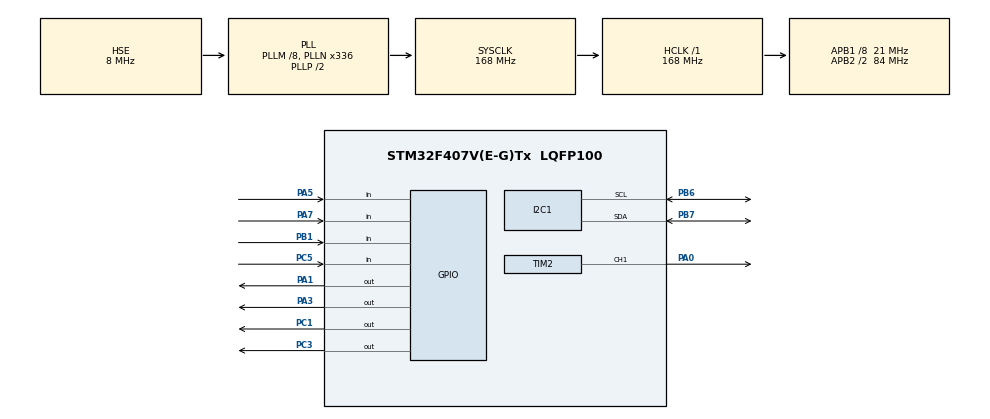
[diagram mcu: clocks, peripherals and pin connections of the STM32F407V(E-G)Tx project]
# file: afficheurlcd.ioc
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Mcu.Family=STM32F4
Mcu.Name=STM32F407V(E-G)Tx
Mcu.Package=LQFP100
NVIC.PriorityGroup=NVIC_PRIORITYGROUP_0
PA0-WKUP.Signal=S_TIM2_CH1_ETR
PA1.Signal=GPIO_Output
PA13.Mode=Serial_Wire
PA13.Signal=SYS_JTMS-SWDIO
PA14.Mode=Serial_Wire
PA14.Signal=SYS_JTCK-SWCLK
PA3.Signal=GPIO_Output
PA5.Signal=GPIO_Input
PA7.Signal=GPIO_Input
PB1.Signal=GPIO_Input
PB6.Mode=I2C
PB6.Signal=I2C1_SCL
PB7.Mode=I2C
PB7.Signal=I2C1_SDA
PC1.Signal=GPIO_Output
PC3.Signal=GPIO_Output
PC5.Signal=GPIO_Input
PH0-OSC_IN.Mode=HSE-External-Oscillator
PH0-OSC_IN.Signal=RCC_OSC_IN
PH1-OSC_OUT.Mode=HSE-External-Oscillator
PH1-OSC_OUT.Signal=RCC_OSC_OUT
ProjectManager.HeapSize=0x200
ProjectManager.StackSize=0x400
ProjectManager.TargetToolchain=STM32CubeIDE
RCC.48MHZClocksFreq_Value=48000000
RCC.AHBFreq_Value=168000000
RCC.APB1CLKDivider=RCC_HCLK_DIV8
RCC.APB1Freq_Value=21000000
RCC.APB1TimFreq_Value=42000000
RCC.APB2CLKDivider=RCC_HCLK_DIV2
RCC.APB2Freq_Value=84000000
RCC.APB2TimFreq_Value=168000000
RCC.CortexFreq_Value=168000000
RCC.HCLKFreq_Value=168000000
RCC.HSE_VALUE=8000000
RCC.HSI_VALUE=16000000
RCC.LSE_VALUE=32768
RCC.PLLM=8
RCC.PLLN=336
RCC.PLLQ=7
RCC.PLLSourceVirtual=RCC_PLLSOURCE_HSE
RCC.SYSCLKFreq_VALUE=168000000
RCC.SYSCLKSource=RCC_SYSCLKSOURCE_PLLCLK
RCC.VCOOutputFreq_Value=336000000
SH.S_TIM2_CH1_ETR.0=TIM2_CH1,PWM Generation1 CH1
TIM2.Channel-PWM\ Generation1\ CH1=TIM_CHANNEL_1
TIM2.Period=1000
TIM2.Prescaler=840
board=STM32F407G-DISC1

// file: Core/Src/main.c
/* USER CODE BEGIN Header */
/**
  ******************************************************************************
  * @file           : main.c
  * @brief          : Main program body
  ******************************************************************************
  * @attention
  *
  * Copyright (c) 2024 STMicroelectronics.
  * All rights reserved.
  *
  * This software is licensed under terms that can be found in the LICENSE file
  * in the root directory of this software component.
  * If no LICENSE file comes with this software, it is provided AS-IS.
  *
  ******************************************************************************
  */
/* USER CODE END Header */
#include "main.h"
#include "STM32F407_KeypadDriver.h"
#include "i2c-lcd.h"
#include<string.h>

I2C_HandleTypeDef hi2c1;

TIM_HandleTypeDef htim2;

void SystemClock_Config(void);
static void MX_GPIO_Init(void);
static void MX_I2C1_Init(void);
static void MX_TIM2_Init(void);

/* USER CODE BEGIN 0 */
#define PASSWORD "1234"
/* USER CODE END 0 */

int main(void)
{

  /* MCU Configuration--------------------------------------------------------*/

  /* Reset of all peripherals, Initializes the Flash interface and the Systick. */
  HAL_Init();

  /* Configure the system clock */
  SystemClock_Config();

  /* Initialize all configured peripherals */
  MX_GPIO_Init();
  MX_I2C1_Init();
  MX_TIM2_Init();
  /* USER CODE BEGIN 2 */
  HAL_TIM_PWM_Start(&htim2, TIM_CHANNEL_1);//start pwm
  lcd_init ();
  KEYPAD_Init();
  lcd_clear();
   lcd_send_cmd(0x80);
   lcd_send_string("KEY:");
  /* USER CODE END 2 */
   htim2.Instance->CCR1 =75;
   char Key = KEYPAD_NOT_PRESSED;
   char Par = KEYPAD_NOT_PRESSED;
   char inputPassword[5];
   inputPassword[4] = '\0';

   uint8_t i=0;
   uint8_t b=0;
  // uint8_t j;
  /* Infinite loop */
  while (1)
  {

	 	 //  lcd_send_cmd(0x80);
	 	  // lcd_send_string("KEY:");
	 	    /* USER CODE END WHILE */
	 		  Key =KEYPAD_Read();

	 		   if(Key != KEYPAD_NOT_PRESSED)
	 		  	     {
	 			   uint8_t adresse=0x85;
	 		  	    	 lcd_send_cmd(adresse+i);
	 		  	    	lcd_send_data('*');
	 		  	    	inputPassword[i]=Key;

	 		  	    	//lcd_send_cmd(0x87);
	 		  	     // lcd_send_data(inputPassword[i]);
	 		  	         i++;

	 		  	    	// HAL_Delay(1000);
	 		  	    //	 lcd_send_cmd(0x85);
	 		  	    	//lcd_send_data(' ');

	 		  	  	 }
	 		   if(i==4)
	 		   {
	 			   if (strcmp(inputPassword, PASSWORD) == 0)
	 			   {
	 				   lcd_clear();
	 				   lcd_send_cmd(0x80);
	 				      lcd_send_string("Password Correct");
	 				      htim2.Instance->CCR1 =125;
	 				     lcd_send_cmd(0xC0);
	 				    lcd_send_string("D:locked door");
	 				    while(1)
	 				   {

	 				    //HAL_Delay(100);
	 				    Par=KEYPAD_Read();
	 				    if(Par=='D')
	 				    {
	 				    	 htim2.Instance->CCR1 =75;
	 				    	break;
	 				    	}
	 				    	}

	 				      i++;
	 			   	           } else {
	 			   	        	 lcd_clear();
	 			   	        	lcd_send_cmd(0x80);
	 			   	        	lcd_send_string("Password incorrect");
	 			   	        	HAL_Delay(2000);
	 			   	        	b++;
	 			   	        	if(b==3)
	 			   	        	{
	 			   	        		lcd_clear();
	 	   	        			lcd_send_cmd(0x80);
	 	   	        		lcd_send_string("door blocked");
	 	   	        		//HAL_Delay(1000);
	 	   	        		lcd_send_cmd(0xC0);
	 	   	        		lcd_send_string("#:exit");
	 			   	        		while(1)
	 			   	        			{

	 			   	        		//HAL_Delay(100);
	 			   	        		Par=KEYPAD_Read();
	 			   	        		if(Par=='#')
	 			   	        		{
	 			   	        			b=0;
	 			   	        			break;
	 			   	        		}
	 			   	        			}

	 			   	        	}
	 			   	        /* lcd_send_cmd(0x96);
	 			   	      lcd_send_string("reste");
	 			   	      	lcd_send_cmd(0x101);
	 			   	      		lcd_send_data(j);
	 			   	      		lcd_send_cmd(0x102);
	 			   	      		lcd_send_string("tent");*/

	 			   	        	i++;
	 			   	        // htim2.Instance->CCR1 =125;
	 			   	        // HAL_Delay(2000);
	 			   	           }
	 			if(i==5)
	 			{
	 				lcd_clear();
	 				   lcd_send_cmd(0x80);
	 				   lcd_send_string("KEY:");
	 				   i=0;
	 			}
	     /* USER CODE BEGIN 3 */
	   }
  }
}
void SystemClock_Config(void)
{
  RCC_OscInitTypeDef RCC_OscInitStruct = {0};
  RCC_ClkInitTypeDef RCC_ClkInitStruct = {0};

  /** Configure the main internal regulator output voltage
  */
  __HAL_RCC_PWR_CLK_ENABLE();
  __HAL_PWR_VOLTAGESCALING_CONFIG(PWR_REGULATOR_VOLTAGE_SCALE1);
  /** Initializes the RCC Oscillators according to the specified parameters
  * in the RCC_OscInitTypeDef structure.
  */
  RCC_OscInitStruct.OscillatorType = RCC_OSCILLATORTYPE_HSE;
  RCC_OscInitStruct.HSEState = RCC_HSE_ON;
  RCC_OscInitStruct.PLL.PLLState = RCC_PLL_ON;
  RCC_OscInitStruct.PLL.PLLSource = RCC_PLLSOURCE_HSE;
  RCC_OscInitStruct.PLL.PLLM = 8;
  RCC_OscInitStruct.PLL.PLLN = 336;
  RCC_OscInitStruct.PLL.PLLP = RCC_PLLP_DIV2;
  RCC_OscInitStruct.PLL.PLLQ = 7;
  if (HAL_RCC_OscConfig(&RCC_OscInitStruct) != HAL_OK)
  {
    Error_Handler();
  }
  /** Initializes the CPU, AHB and APB buses clocks
  */
  RCC_ClkInitStruct.ClockType = RCC_CLOCKTYPE_HCLK|RCC_CLOCKTYPE_SYSCLK
                              |RCC_CLOCKTYPE_PCLK1|RCC_CLOCKTYPE_PCLK2;
  RCC_ClkInitStruct.SYSCLKSource = RCC_SYSCLKSOURCE_PLLCLK;
  RCC_ClkInitStruct.AHBCLKDivider = RCC_SYSCLK_DIV1;
  RCC_ClkInitStruct.APB1CLKDivider = RCC_HCLK_DIV8;
  RCC_ClkInitStruct.APB2CLKDivider = RCC_HCLK_DIV2;

  if (HAL_RCC_ClockConfig(&RCC_ClkInitStruct, FLASH_LATENCY_5) != HAL_OK)
  {
    Error_Handler();
  }
}

static void MX_I2C1_Init(void)
{

  hi2c1.Instance = I2C1;
  hi2c1.Init.ClockSpeed = 100000;
  hi2c1.Init.DutyCycle = I2C_DUTYCYCLE_2;
  hi2c1.Init.OwnAddress1 = 0;
  hi2c1.Init.AddressingMode = I2C_ADDRESSINGMODE_7BIT;
  hi2c1.Init.DualAddressMode = I2C_DUALADDRESS_DISABLE;
  hi2c1.Init.OwnAddress2 = 0;
  hi2c1.Init.GeneralCallMode = I2C_GENERALCALL_DISABLE;
  hi2c1.Init.NoStretchMode = I2C_NOSTRETCH_DISABLE;
  if (HAL_I2C_Init(&hi2c1) != HAL_OK)
  {
    Error_Handler();
  }

}

static void MX_TIM2_Init(void)
{

  TIM_MasterConfigTypeDef sMasterConfig = {0};
  TIM_OC_InitTypeDef sConfigOC = {0};

  htim2.Instance = TIM2;
  htim2.Init.Prescaler = 840;
  htim2.Init.CounterMode = TIM_COUNTERMODE_UP;
  htim2.Init.Period = 1000;
  htim2.Init.ClockDivision = TIM_CLOCKDIVISION_DIV1;
  htim2.Init.AutoReloadPreload = TIM_AUTORELOAD_PRELOAD_DISABLE;
  if (HAL_TIM_PWM_Init(&htim2) != HAL_OK)
  {
    Error_Handler();
  }
  sMasterConfig.MasterOutputTrigger = TIM_TRGO_RESET;
  sMasterConfig.MasterSlaveMode = TIM_MASTERSLAVEMODE_DISABLE;
  if (HAL_TIMEx_MasterConfigSynchronization(&htim2, &sMasterConfig) != HAL_OK)
  {
    Error_Handler();
  }
  sConfigOC.OCMode = TIM_OCMODE_PWM1;
  sConfigOC.Pulse = 0;
  sConfigOC.OCPolarity = TIM_OCPOLARITY_HIGH;
  sConfigOC.OCFastMode = TIM_OCFAST_DISABLE;
  if (HAL_TIM_PWM_ConfigChannel(&htim2, &sConfigOC, TIM_CHANNEL_1) != HAL_OK)
  {
    Error_Handler();
  }
  HAL_TIM_MspPostInit(&htim2);

}

static void MX_GPIO_Init(void)
{
  GPIO_InitTypeDef GPIO_InitStruct = {0};

  /* GPIO Ports Clock Enable */
  __HAL_RCC_GPIOH_CLK_ENABLE();
  __HAL_RCC_GPIOC_CLK_ENABLE();
  __HAL_RCC_GPIOA_CLK_ENABLE();
  __HAL_RCC_GPIOB_CLK_ENABLE();

  /*Configure GPIO pin Output Level */
  HAL_GPIO_WritePin(GPIOC, GPIO_PIN_1|GPIO_PIN_3, GPIO_PIN_RESET);

  /*Configure GPIO pin Output Level */
  HAL_GPIO_WritePin(GPIOA, GPIO_PIN_1|GPIO_PIN_3, GPIO_PIN_RESET);

  /*Configure GPIO pins : PC1 PC3 */
  GPIO_InitStruct.Pin = GPIO_PIN_1|GPIO_PIN_3;
  GPIO_InitStruct.Mode = GPIO_MODE_OUTPUT_PP;
  GPIO_InitStruct.Pull = GPIO_NOPULL;
  GPIO_InitStruct.Speed = GPIO_SPEED_FREQ_LOW;
  HAL_GPIO_Init(GPIOC, &GPIO_InitStruct);

  /*Configure GPIO pins : PA1 PA3 */
  GPIO_InitStruct.Pin = GPIO_PIN_1|GPIO_PIN_3;
  GPIO_InitStruct.Mode = GPIO_MODE_OUTPUT_PP;
  GPIO_InitStruct.Pull = GPIO_NOPULL;
  GPIO_InitStruct.Speed = GPIO_SPEED_FREQ_LOW;
  HAL_GPIO_Init(GPIOA, &GPIO_InitStruct);

  /*Configure GPIO pins : PA5 PA7 */
  GPIO_InitStruct.Pin = GPIO_PIN_5|GPIO_PIN_7;
  GPIO_InitStruct.Mode = GPIO_MODE_INPUT;
  GPIO_InitStruct.Pull = GPIO_NOPULL;
  HAL_GPIO_Init(GPIOA, &GPIO_InitStruct);

  /*Configure GPIO pin : PC5 */
  GPIO_InitStruct.Pin = GPIO_PIN_5;
  GPIO_InitStruct.Mode = GPIO_MODE_INPUT;
  GPIO_InitStruct.Pull = GPIO_NOPULL;
  HAL_GPIO_Init(GPIOC, &GPIO_InitStruct);

  /*Configure GPIO pin : PB1 */
  GPIO_InitStruct.Pin = GPIO_PIN_1;
  GPIO_InitStruct.Mode = GPIO_MODE_INPUT;
  GPIO_InitStruct.Pull = GPIO_NOPULL;
  HAL_GPIO_Init(GPIOB, &GPIO_InitStruct);

}

void Error_Handler(void)
{
  __disable_irq();
  while (1)
  {
  }
}
